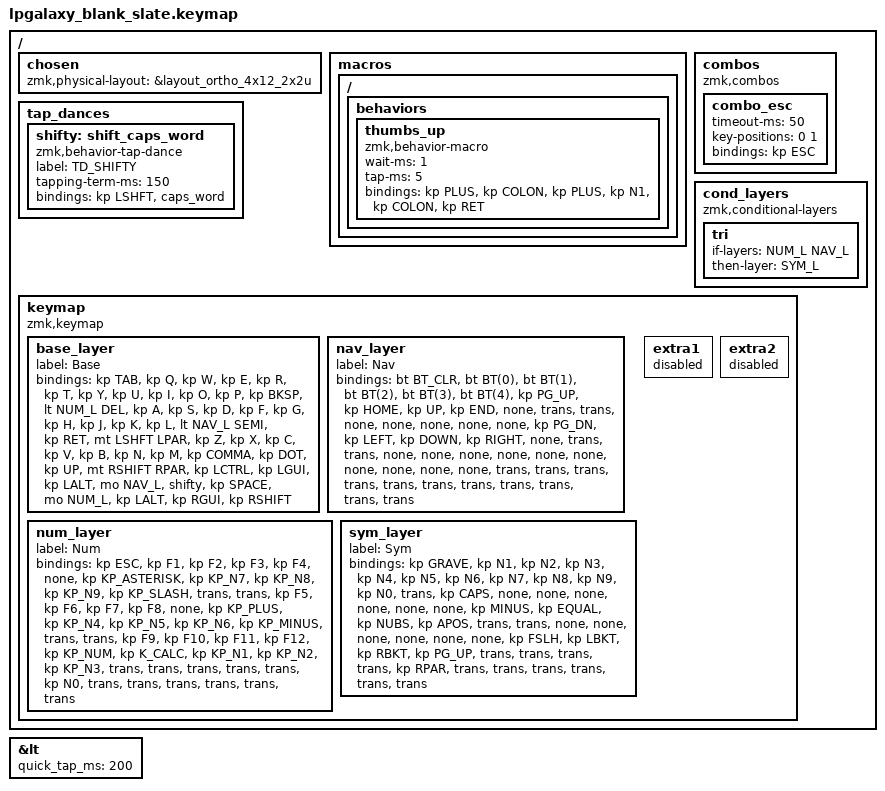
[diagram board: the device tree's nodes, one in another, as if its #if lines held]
/*
 * Copyright (c) 2022 Pete Johanson
 *
 * SPDX-License-Identifier: MIT
 */

#include <behaviors.dtsi>
#include <dt-bindings/zmk/keys.h>
#include <dt-bindings/zmk/bt.h>
#include <dt-bindings/zmk/outputs.h>

#define QWERTY_BASE 1

#define TBLE_ORTHO   1
// #define TBLE_MIT     1
// #define TBLE_DUAL_2U 1

#define NAV_L 1
#define NUM_L 2
#define SYM_L 3

// Using layer taps on thumbs, having quick tap as well helps w/ repeating space/backspace
&lt { quick_tap_ms = <200>; };

#define BT(n) BT_SEL n

/ {
    chosen {
       zmk,physical-layout =
#ifdef TBLE_DUAL_2U
                       &layout_ortho_4x12_2x2u;
#elif defined(TBLE_MIT)
                       &layout_ortho_4x12_1x2u;
#else
                       &layout_ortho_4x12_all1u;
#endif
    };

    macros {
      ZMK_MACRO(thumbs_up,
		wait-ms = <1>;
		tap-ms = <5>;
                bindings = <&kp PLUS &kp COLON &kp PLUS &kp N1 &kp COLON &kp RET>;
		)
    };

    combos {
        compatible = "zmk,combos";
        combo_esc {
            timeout-ms = <50>;
            key-positions = <0 1>;
            bindings = <&kp ESC>;
        };
    };

    tap_dances {
    	shifty: shift_caps_word {
		compatible = "zmk,behavior-tap-dance";
		label = "TD_SHIFTY";
		#binding-cells = <0>;
		tapping-term-ms = <150>;
		bindings = <&kp LSHFT>, <&caps_word>;
	};
    };

// Conditional layer only when we have less thumb keys
#ifdef TBLE_DUAL_2U
    cond_layers {
        compatible = "zmk,conditional-layers";
	tri {
	    if-layers = <NUM_L NAV_L>;
	    then-layer = <SYM_L>;
        };
    };
#endif

    keymap {
        compatible = "zmk,keymap";

        base_layer {
            label = "Base";
            bindings = <
#ifdef QWERTY_BASE
 &kp TAB         &kp Q      &kp W      &kp E       &kp R          &kp T          &kp Y            &kp U          &kp I       &kp O      &kp P           &kp BKSP
 &lt NUM_L DEL   &kp A      &kp S      &kp D       &kp F          &kp G          &kp H            &kp J          &kp K       &kp L      &lt NAV_L SEMI  &kp RET
 &mt LSHFT LPAR  &kp Z      &kp X      &kp C       &kp V          &kp B          &kp N            &kp M          &kp COMMA   &kp DOT    &kp UP          &mt RSHIFT RPAR
#else
 &kp ESC    &kp Q      &kp W      &kp F       &kp P          &kp B          &kp J            &kp L          &kp U       &kp Y      &kp QUOT      &kp BKSP
 &kp TAB    &kp A      &kp R      &kp S       &kp T          &kp G          &kp M            &kp N          &kp E       &kp I      &kp O         &kp QUOT
 &kp LSHFT  &kp Z      &kp X      &kp C       &kp D          &kp V          &kp K            &kp H          &kp COMMA   &kp DOT    &kp SEMI      &kp RET
#endif
#ifdef TBLE_DUAL_2U
 &kp LCTRL  &kp LGUI   &kp LALT   &mo NAV_L         &shifty                        &kp SPACE                &mo NUM_L   &kp LALT   &kp RGUI      &kp RSHIFT
#elif defined(TBLE_MIT)
 &kp LCTRL  &mo SYM_L   &kp LGUI  &kp LALT    &mo NAV_L          &kp SPACE                   &mo NUM_L      &kp LEFT    &kp UP     &kp DOWN      &kp RIGHT
#else
 &kp LCTRL       &kp LGUI   &kp LALT  &kp LG(LC(D)) &lt SYM_L SPACE &kp LG(LC(LEFT)) &kp LG(LC(RIGHT)) &kp SPACE  &kp RALT    &kp LEFT   &kp DOWN      &kp RIGHT
#endif
            >;
        };

        nav_layer {
            label = "Nav";
            bindings = <
&bt BT_CLR &bt BT(0)  &bt BT(1)  &bt BT(2)   &bt BT(3)       &bt BT(4)    &kp PG_UP  &kp HOME       &kp UP      &kp END       &none      &trans
&trans     &none      &none      &none       &none           &none        &kp PG_DN  &kp LEFT       &kp DOWN    &kp RIGHT     &none      &trans
&trans     &none      &none      &none       &none           &none        &none      &none          &none       &none         &none      &trans
#ifdef TBLE_DUAL_2U
&trans  &trans        &trans     &trans              &trans                    &trans       &trans         &trans &trans &trans
#elif defined(TBLE_MIT)
&trans  &trans        &trans     &trans      &trans                &trans             &trans      &trans   &trans &trans &trans
#else
&trans      &trans      &trans    &trans      &trans         &trans       &tog NAV_L &trans         &studio_unlock &trans     &trans     &trans
#endif
            >;
        };

        num_layer {
            label = "Num";
            bindings = <
&kp ESC    &kp F1   &kp F2   &kp F3   &kp F4    &none       &kp KP_ASTERISK  &kp KP_N7     &kp KP_N8      &kp KP_N9       &kp KP_SLASH     &trans
&trans     &kp F5   &kp F6   &kp F7   &kp F8    &none       &kp KP_PLUS      &kp KP_N4     &kp KP_N5      &kp KP_N6       &kp KP_MINUS     &trans
&trans     &kp F9   &kp F10  &kp F11  &kp F12   &kp KP_NUM  &kp K_CALC       &kp KP_N1     &kp KP_N2      &kp KP_N3       &trans           &trans
#ifdef TBLE_DUAL_2U
&trans  &trans       &trans     &kp N0              &trans                 &trans            &trans         &trans &trans &trans
#elif defined(TBLE_MIT)
&trans  &trans       &trans     &kp N0      &trans           &none            &trans        &kp DEL      &trans &trans &trans
#else
&trans     &trans   &trans   &trans   &trans    &trans      &tog NUM_L       &kp KP_N0     &kp KP_DOT     &trans          &trans           &trans
#endif
            >;
        };

        sym_layer {
            label = "Sym";
            bindings = <
&kp GRAVE  &kp N1     &kp N2     &kp N3      &kp N4       &kp N5       &kp N6     &kp N7    &kp N8       &kp N9       &kp N0     &trans
&kp CAPS   &none      &none      &none       &none        &none        &none      &kp MINUS &kp EQUAL    &kp NUBS     &kp APOS   &trans
&trans     &none      &none      &none       &none        &none        &none      &kp FSLH  &kp LBKT     &kp RBKT     &kp PG_UP  &trans
#ifdef TBLE_DUAL_2U
&trans &trans        &trans     &kp RPAR                &trans                    &trans       &trans         &trans &trans &trans
#elif defined(TBLE_MIT)
&trans &trans        &trans     &kp RPAR        &trans                &trans             &trans      &trans   &trans &trans &trans
#else
&trans     &trans     &trans     &trans      &none        &trans       &tog SYM_L &kp RSHFT    &kp RCTRL    &kp HOME     &kp PG_DN  &kp END
#endif
            >;
        };

	extra1 {
            status = "reserved";
        };

        extra2 {
            status = "reserved";
        };


    };
};

